# tviic2d6mddr register map
Vendor: Cypress Semiconductor; Series: tviic2d6mddr; File version: 1.0
CPU: CM7 r0p1, little endian, MPU, FPU, VTOR, 3 interrupt priority bits
Registers are 32-bit, read-write, reset 0x0 unless marked. A register's access mark holds for its fields unless they carry their own. Offsets are from the block's base; [hi:lo] are bit positions; lines under a group give offsets from that group; {n}, {i} and the like mark numbered series.

## FAULT — Fault structures
Base 0x40210000
{0x0+0x100*i} STRUCT[{i}] (i=0..3) group — Fault structure
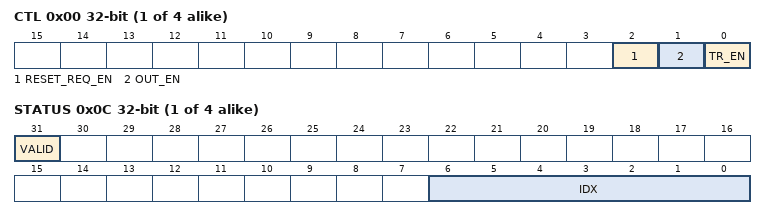
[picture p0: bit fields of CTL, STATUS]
  0x00 CTL — Fault control
    [2] RESET_REQ_EN — Reset request enable: '0': Disabled. '1': Enabled. The output reset request signal 'fault_reset_req' reflects STATUS.VALID. This reset causes a warm/soft/core reset. This warm/soft/core reset does not affect the fault logic STATUS, DATA0, ..., DATA3 registers (allowing for post soft reset failure analysis). The 'fault_reset_req' signals of the individual fault report structures are combined (logically OR'd) into a single SRSS 'fault_reset_req' signal.
    [1] OUT_EN — IO output signal enable: '0': Disabled. The IO output signal 'fault_out' is '0'. The IO output enable signal 'fault_out_en' is '0'. '1': Enabled. The IO output signal 'fault_out' reflects STATUS.VALID. The IO output enable signal 'fault_out_en' is '1'.
    [0] TR_EN — Trigger output enable: '0': Disabled. The trigger output 'tr_fault' is '0'. '1': Enabled. The trigger output 'tr_fault' reflects STATUS.VALID. The trigger can be used to initiate a Datawire transfer of the FAULT data (FAULT_DATA0 through FAULT_DATA3).
  0x0C STATUS (reset mask 0x80000000) — Fault status
    [31] VALID — Valid indication: '0': Invalid. '1': Valid. STATUS.IDX, DATA0, ..., DATA3 specify the fault. Note: Typically, HW sets this field to '1' (on an activated HW fault source that is 'enabled' by the MASK registers) and SW clears this field to '0' (typically by boot code SW (after a warm system reset, when the fault is handled). In this typical use case scenario, the HW source fault data is simultaneously captured into DATA0, ..., DATA3 when the VALID field is set to '1'. An exceptional SW use case scenario is identified as well. In this scenario, SW sets this field to '1' with a fault source index different to one of the defined HW fault sources. SW update is not restricted by the MASK registers). In both use case scenarios, the following holds: - STATUS.IDX, DATA0, ..., DATA3 can only be written when STATUS.VALID is '0'; the fault structure is not in use yet. Writing STATUS.VALID to '1' effectively locks the fault structure (until SW clears STATUS.VALID to '0'). This restriction requires a SW update to sequentially update the DATA registers followed by an update of the STATUS register. Note: For the exceptional SW use case, sequential updates to the DATA and STATUS registers may be 'interrupted' by a HW fault capture. In this case, the SW DATA register updates are overwritten by the HW update (and the STATUS.IDX field will reflect the HW capture)
    [6:0] IDX — The fault source index for which fault information is captured in DATA0 through DATA3. The fault information is fault source specific and described below. Note: this register field (and associated fault source data in DATA0 through DATA3) should only be considered valid, when VALID is '1'. The description of the encoded meaning of this field is comes from the Fault assignment in the Product TRM.
  {0x10+4j} DATA[{j}] (j=0..3) reset not defined — Fault data
    [31:0] DATA — Captured fault source data. Note: the DATA registers can only be written when STATUS.VALID is '0'. Note: the fault source index STATUS.IDX specifies the format of the DATA registers.
  0x40 PENDING0 ro reset not defined — Fault pending 0
    [31:0] SOURCE — This field specifies the following sources: Bit 0: CM0 MPU. Bit 1: CRYPTO MPU. Bit 2: DW 0 MPU. Bit 3: DW 1 MPU. Bit 4: DMA controller MPU. ... Bit 15: DAP MPU. Bit 16: CM4 system bus MPU. Bit 17: CM4 code bus MPU (for non FLASH controller accesses). Bit 18: CM4 code bus MPU (for FLASH controller accesses).
  0x44 PENDING1 ro reset not defined — Fault pending 1
    [31:0] SOURCE — This field specifies the following sources: Bit 0: Peripheral group 0 PPU. Bit 1: Peripheral group 1 PPU. Bit 2: Peripheral group 2 PPU. Bit 3: Peripheral group 3 PPU. Bit 4: Peripheral group 4 PPU. Bit 5: Peripheral group 5 PPU. Bit 6: Peripheral group 6 PPU. Bit 7: Peripheral group 7 PPU. ... Bit 15: Peripheral group 15 PPU. Bit 16 - 31: See STATUS register.
  0x48 PENDING2 ro reset not defined — Fault pending 2
    [31:0] SOURCE — This field specifies the following sources: Bit 0 - 31: See STATUS register.
  0x50 MASK0 — Fault mask 0
    [31:0] SOURCE — Fault source enables: Bits 31-0: Fault sources 31 to 0.
  0x54 MASK1 — Fault mask 1
    [31:0] SOURCE — Fault source enables: Bits 31-0: Fault sources 63 to 32.
  0x58 MASK2 — Fault mask 2
    [31:0] SOURCE — Fault source enables: Bits 31-0: Fault sources 95 to 64.
  0xC0 INTR — Interrupt
    [0] FAULT — This interrupt cause field is activated (HW sets the field to '1') when an enabled (MASK0/MASK1/MASK2) pending fault source is captured: - STATUS.VALID is set to '1'. - STATUS.IDX specifies the fault source index. - DATA0 through DATA3 captures the fault source data. SW writes a '1' to this field to clear the interrupt cause to '0'. SW clear STATUS.VALID to '0' to enable capture of the next fault. Note that when there is an enabled pending fault source, the pending fault source is captured immediately and INTR.FAULT is immediately activated (set to '1').
  0xC4 INTR_SET — Interrupt set
    [0] FAULT — SW writes a '1' to this field to set the corresponding field in the INTR register.
  0xC8 INTR_MASK — Interrupt mask
    [0] FAULT — Mask bit for corresponding field in the INTR register.
  0xCC INTR_MASKED ro — Interrupt masked
    [0] FAULT — Logical and of corresponding INTR and INTR_MASK fields.
